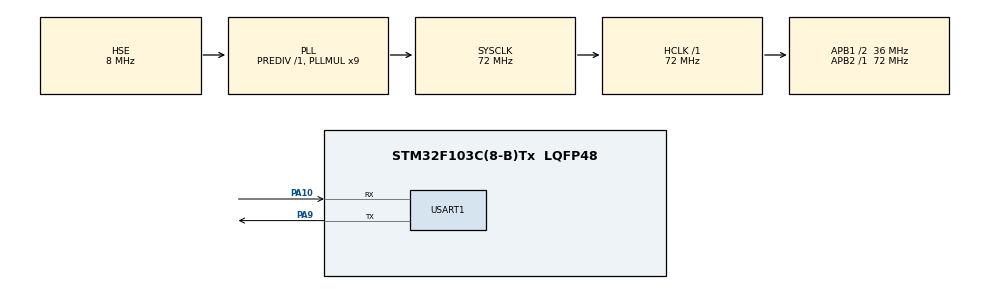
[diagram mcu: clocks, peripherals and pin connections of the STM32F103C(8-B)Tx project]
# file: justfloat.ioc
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Mcu.Family=STM32F1
Mcu.Name=STM32F103C(8-B)Tx
Mcu.Package=LQFP48
NVIC.PriorityGroup=NVIC_PRIORITYGROUP_4
PA10.Mode=Asynchronous
PA10.Signal=USART1_RX
PA13.Mode=Serial_Wire
PA13.Signal=SYS_JTMS-SWDIO
PA14.Mode=Serial_Wire
PA14.Signal=SYS_JTCK-SWCLK
PA9.Mode=Asynchronous
PA9.Signal=USART1_TX
PD0-OSC_IN.Mode=HSE-External-Oscillator
PD0-OSC_IN.Signal=RCC_OSC_IN
PD1-OSC_OUT.Mode=HSE-External-Oscillator
PD1-OSC_OUT.Signal=RCC_OSC_OUT
ProjectManager.HeapSize=0x200
ProjectManager.StackSize=0x400
ProjectManager.TargetToolchain=MDK-ARM V5.32
RCC.AHBFreq_Value=72000000
RCC.APB1CLKDivider=RCC_HCLK_DIV2
RCC.APB1Freq_Value=36000000
RCC.APB1TimFreq_Value=72000000
RCC.APB2Freq_Value=72000000
RCC.APB2TimFreq_Value=72000000
RCC.HCLKFreq_Value=72000000
RCC.PLLMUL=RCC_PLL_MUL9
RCC.PLLSourceVirtual=RCC_PLLSOURCE_HSE
RCC.SYSCLKFreq_VALUE=72000000
RCC.SYSCLKSource=RCC_SYSCLKSOURCE_PLLCLK
RCC.USBFreq_Value=72000000
USART1.VirtualMode=VM_ASYNC
board=custom

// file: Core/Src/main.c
/* USER CODE BEGIN Header */
/**
  ******************************************************************************
  * @file           : main.c
  * @brief          : Main program body (JustFloat 双通道正弦波发送)
  ******************************************************************************
  * @attention
  *
  * Copyright (c) 2025 STMicroelectronics.
  * All rights reserved.
  *
  * This software is licensed under terms that can be found in the LICENSE file
  * in the root directory of this software component.
  * If no LICENSE file comes with this software, it is provided AS-IS.
  *
  ******************************************************************************
  */
/* USER CODE END Header */

#include "main.h"
#include "usart.h"
#include "gpio.h"

/* USER CODE BEGIN Includes */
#include <math.h>
/* USER CODE END Includes */

/* USER CODE BEGIN PV */
float x = 0.0f;
const float dt = 0.01f;
/* USER CODE END PV */

void SystemClock_Config(void);
/* USER CODE BEGIN PFP */
// USART1 单字节发送函数
void USART1_SendByte(uint8_t data);
// JustFloat 协议发送函数
void JustFloat_Send(float *data, uint8_t channel_count);
/* USER CODE END PFP */

/* USER CODE BEGIN 0 */
/**
 * @brief  USART1 单字节发送（轮询方式，确保数据发送完成）
 * @param  data: 要发送的字节
 * @retval None
 */
void USART1_SendByte(uint8_t data) {
    // 等待发送寄存器空
    while (__HAL_UART_GET_FLAG(&huart1, UART_FLAG_TXE) == RESET);
    // 写入数据寄存器
    huart1.Instance->DR = data;
}

/**
 */
void JustFloat_Send(float *data, uint8_t channel_count) {
    // 1. 发送所有通道的float数据（每个float拆分为4字节）
    for (uint8_t ch = 0; ch < channel_count; ch++) {
        uint8_t *byte_ptr = (uint8_t *)&data[ch];
        for (uint8_t i = 0; i < 4; i++) {
            USART1_SendByte(byte_ptr[i]);
        }
    }

    // 2. 发送 JustFloat 协议要求的固定帧尾
    uint8_t tail[4] = {0x00, 0x00, 0x80, 0x7f};
    for (uint8_t i = 0; i < 4; i++) {
        USART1_SendByte(tail[i]);
    }
}
/* USER CODE END 0 */

/**
 */
int main(void)
{
  HAL_Init();
  SystemClock_Config();
  MX_GPIO_Init();
  MX_USART1_UART_Init();

  while (1)
  {
    // 生成双通道正弦波数据
    float ch_data[2] = {
        sin(x),       // 通道0：正弦波1
        sin(2 * x)    // 通道1：正弦波2
    };

    JustFloat_Send(ch_data, 2);

    x += dt;

    HAL_Delay(10);

  }
}

/**
 * @brief
 * @retval None
 */
void SystemClock_Config(void)
{
  RCC_OscInitTypeDef RCC_OscInitStruct = {0};
  RCC_ClkInitTypeDef RCC_ClkInitStruct = {0};

  RCC_OscInitStruct.OscillatorType = RCC_OSCILLATORTYPE_HSE;
  RCC_OscInitStruct.HSEState = RCC_HSE_ON;
  RCC_OscInitStruct.HSEPredivValue = RCC_HSE_PREDIV_DIV1;
  RCC_OscInitStruct.HSIState = RCC_HSI_ON;
  RCC_OscInitStruct.PLL.PLLState = RCC_PLL_ON;
  RCC_OscInitStruct.PLL.PLLSource = RCC_PLLSOURCE_HSE;
  RCC_OscInitStruct.PLL.PLLMUL = RCC_PLL_MUL9;
  if (HAL_RCC_OscConfig(&RCC_OscInitStruct) != HAL_OK)
  {
    Error_Handler();
  }

  RCC_ClkInitStruct.ClockType = RCC_CLOCKTYPE_HCLK|RCC_CLOCKTYPE_SYSCLK
                              |RCC_CLOCKTYPE_PCLK1|RCC_CLOCKTYPE_PCLK2;
  RCC_ClkInitStruct.SYSCLKSource = RCC_SYSCLKSOURCE_PLLCLK;
  RCC_ClkInitStruct.AHBCLKDivider = RCC_SYSCLK_DIV1;
  RCC_ClkInitStruct.APB1CLKDivider = RCC_HCLK_DIV2;
  RCC_ClkInitStruct.APB2CLKDivider = RCC_HCLK_DIV1;

  if (HAL_RCC_ClockConfig(&RCC_ClkInitStruct, FLASH_LATENCY_2) != HAL_OK)
  {
    Error_Handler();
  }
}

/**
 * @brief
 * @retval None
 */
void Error_Handler(void)
{
  __disable_irq();
  while (1)
  {
  }
}
